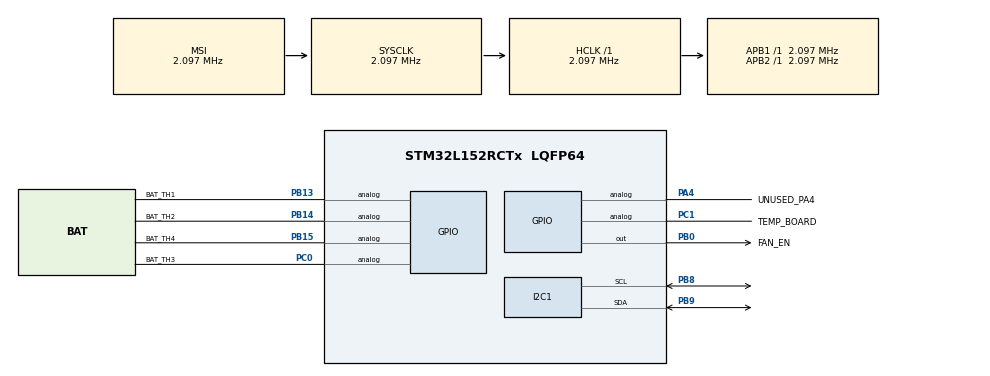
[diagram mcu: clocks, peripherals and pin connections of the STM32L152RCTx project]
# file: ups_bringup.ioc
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Mcu.Family=STM32L1
Mcu.Name=STM32L152RCTx
Mcu.Package=LQFP64
NVIC.PriorityGroup=NVIC_PRIORITYGROUP_4
PA13.Mode=Serial_Wire
PA13.Signal=SYS_JTMS-SWDIO
PA14.Mode=Serial_Wire
PA14.Signal=SYS_JTCK-SWCLK
PA4.GPIO_Label=UNUSED_PA4
PA4.Signal=GPIO_Analog
PB8.Mode=I2C
PB8.Signal=I2C1_SCL
PB9.Mode=I2C
PB9.Signal=I2C1_SDA
PB13.GPIO_Label=BAT_TH1
PB13.Signal=GPIO_Analog
PB14.GPIO_Label=BAT_TH2
PB14.Signal=GPIO_Analog
PB15.GPIO_Label=BAT_TH4
PB15.Signal=GPIO_Analog
PB0.GPIO_Label=FAN_EN
PB0.PinState=GPIO_PIN_SET
PB0.Signal=GPIO_Output
PC0.GPIO_Label=BAT_TH3
PC0.Signal=GPIO_Analog
PC1.GPIO_Label=TEMP_BOARD
PC1.Signal=GPIO_Analog
ProjectManager.HeapSize=0x200
ProjectManager.StackSize=0x400
ProjectManager.TargetToolchain=STM32CubeIDE
RCC.AHBFreq_Value=2097000
RCC.APB1Freq_Value=2097000
RCC.APB2Freq_Value=2097000
RCC.HSE_VALUE=24000000
RCC.HSI_VALUE=16000000
RCC.LSE_VALUE=32768
RCC.MSI_VALUE=2097000
RCC.SYSCLKFreq_VALUE=2097000
RCC.VCOOutputFreq_Value=48000000
board=custom

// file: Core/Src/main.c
/* USER CODE BEGIN Header */
/**
  ******************************************************************************
  * @file           : main.c
  * @brief          : Main program body
  ******************************************************************************
  * @attention
  *
  * Copyright (c) 2026 STMicroelectronics.
  * All rights reserved.
  *
  * This software is licensed under terms that can be found in the LICENSE file
  * in the root directory of this software component.
  * If no LICENSE file comes with this software, it is provided AS-IS.
  *
  ******************************************************************************
  */
/* USER CODE END Header */
#include "main.h"

/* USER CODE BEGIN Includes */
#include "thermistors.h"
#include "fan_control.h"
#include "battery_voltage.h"

/* USER CODE END Includes */

I2C_HandleTypeDef hi2c1;

void SystemClock_Config(void);
static void MX_GPIO_Init(void);
static void MX_I2C1_Init(void);

int main(void)
{

  /* MCU Configuration--------------------------------------------------------*/

  /* Reset of all peripherals, Initializes the Flash interface and the Systick. */
  HAL_Init();

  /* Configure the system clock */
  SystemClock_Config();

  /* Initialize all configured peripherals */
  MX_GPIO_Init();
  MX_I2C1_Init();
  /* USER CODE BEGIN 2 */
  Fan_Init();
  (void)Thermistors_Init();
  BatteryVoltage_Init(&hi2c1);

  /* USER CODE END 2 */

  /* Infinite loop */
  /* USER CODE BEGIN WHILE */
  while (1)
  {

	  Thermistors_Poll();
	  Fan_Update();
	  BatteryVoltage_Poll();
	  HAL_Delay(200);

    /* USER CODE END WHILE */

  }
}

void SystemClock_Config(void)
{
  RCC_OscInitTypeDef RCC_OscInitStruct = {0};
  RCC_ClkInitTypeDef RCC_ClkInitStruct = {0};

  /** Configure the main internal regulator output voltage
  */
  __HAL_PWR_VOLTAGESCALING_CONFIG(PWR_REGULATOR_VOLTAGE_SCALE1);

  /** Initializes the RCC Oscillators according to the specified parameters
  * in the RCC_OscInitTypeDef structure.
  */
  RCC_OscInitStruct.OscillatorType = RCC_OSCILLATORTYPE_MSI;
  RCC_OscInitStruct.MSIState = RCC_MSI_ON;
  RCC_OscInitStruct.MSICalibrationValue = 0;
  RCC_OscInitStruct.MSIClockRange = RCC_MSIRANGE_5;
  RCC_OscInitStruct.PLL.PLLState = RCC_PLL_NONE;
  if (HAL_RCC_OscConfig(&RCC_OscInitStruct) != HAL_OK)
  {
    Error_Handler();
  }

  /** Initializes the CPU, AHB and APB buses clocks
  */
  RCC_ClkInitStruct.ClockType = RCC_CLOCKTYPE_HCLK|RCC_CLOCKTYPE_SYSCLK
                              |RCC_CLOCKTYPE_PCLK1|RCC_CLOCKTYPE_PCLK2;
  RCC_ClkInitStruct.SYSCLKSource = RCC_SYSCLKSOURCE_MSI;
  RCC_ClkInitStruct.AHBCLKDivider = RCC_SYSCLK_DIV1;
  RCC_ClkInitStruct.APB1CLKDivider = RCC_HCLK_DIV1;
  RCC_ClkInitStruct.APB2CLKDivider = RCC_HCLK_DIV1;

  if (HAL_RCC_ClockConfig(&RCC_ClkInitStruct, FLASH_LATENCY_0) != HAL_OK)
  {
    Error_Handler();
  }
}

static void MX_I2C1_Init(void)
{

  hi2c1.Instance = I2C1;
  hi2c1.Init.ClockSpeed = 100000;
  hi2c1.Init.DutyCycle = I2C_DUTYCYCLE_2;
  hi2c1.Init.OwnAddress1 = 0;
  hi2c1.Init.AddressingMode = I2C_ADDRESSINGMODE_7BIT;
  hi2c1.Init.DualAddressMode = I2C_DUALADDRESS_DISABLE;
  hi2c1.Init.OwnAddress2 = 0;
  hi2c1.Init.GeneralCallMode = I2C_GENERALCALL_DISABLE;
  hi2c1.Init.NoStretchMode = I2C_NOSTRETCH_DISABLE;
  if (HAL_I2C_Init(&hi2c1) != HAL_OK)
  {
    Error_Handler();
  }

}

static void MX_GPIO_Init(void)
{
  GPIO_InitTypeDef GPIO_InitStruct = {0};

  /* GPIO Ports Clock Enable */
  __HAL_RCC_GPIOA_CLK_ENABLE();
  __HAL_RCC_GPIOB_CLK_ENABLE();

  /* PA4 is unused after removing the battery ADC branch. */
  GPIO_InitStruct.Pin = GPIO_PIN_4;
  GPIO_InitStruct.Mode = GPIO_MODE_ANALOG;
  GPIO_InitStruct.Pull = GPIO_NOPULL;
  HAL_GPIO_Init(GPIOA, &GPIO_InitStruct);

}

void Error_Handler(void)
{
  __disable_irq();
  while (1)
  {
  }
}
